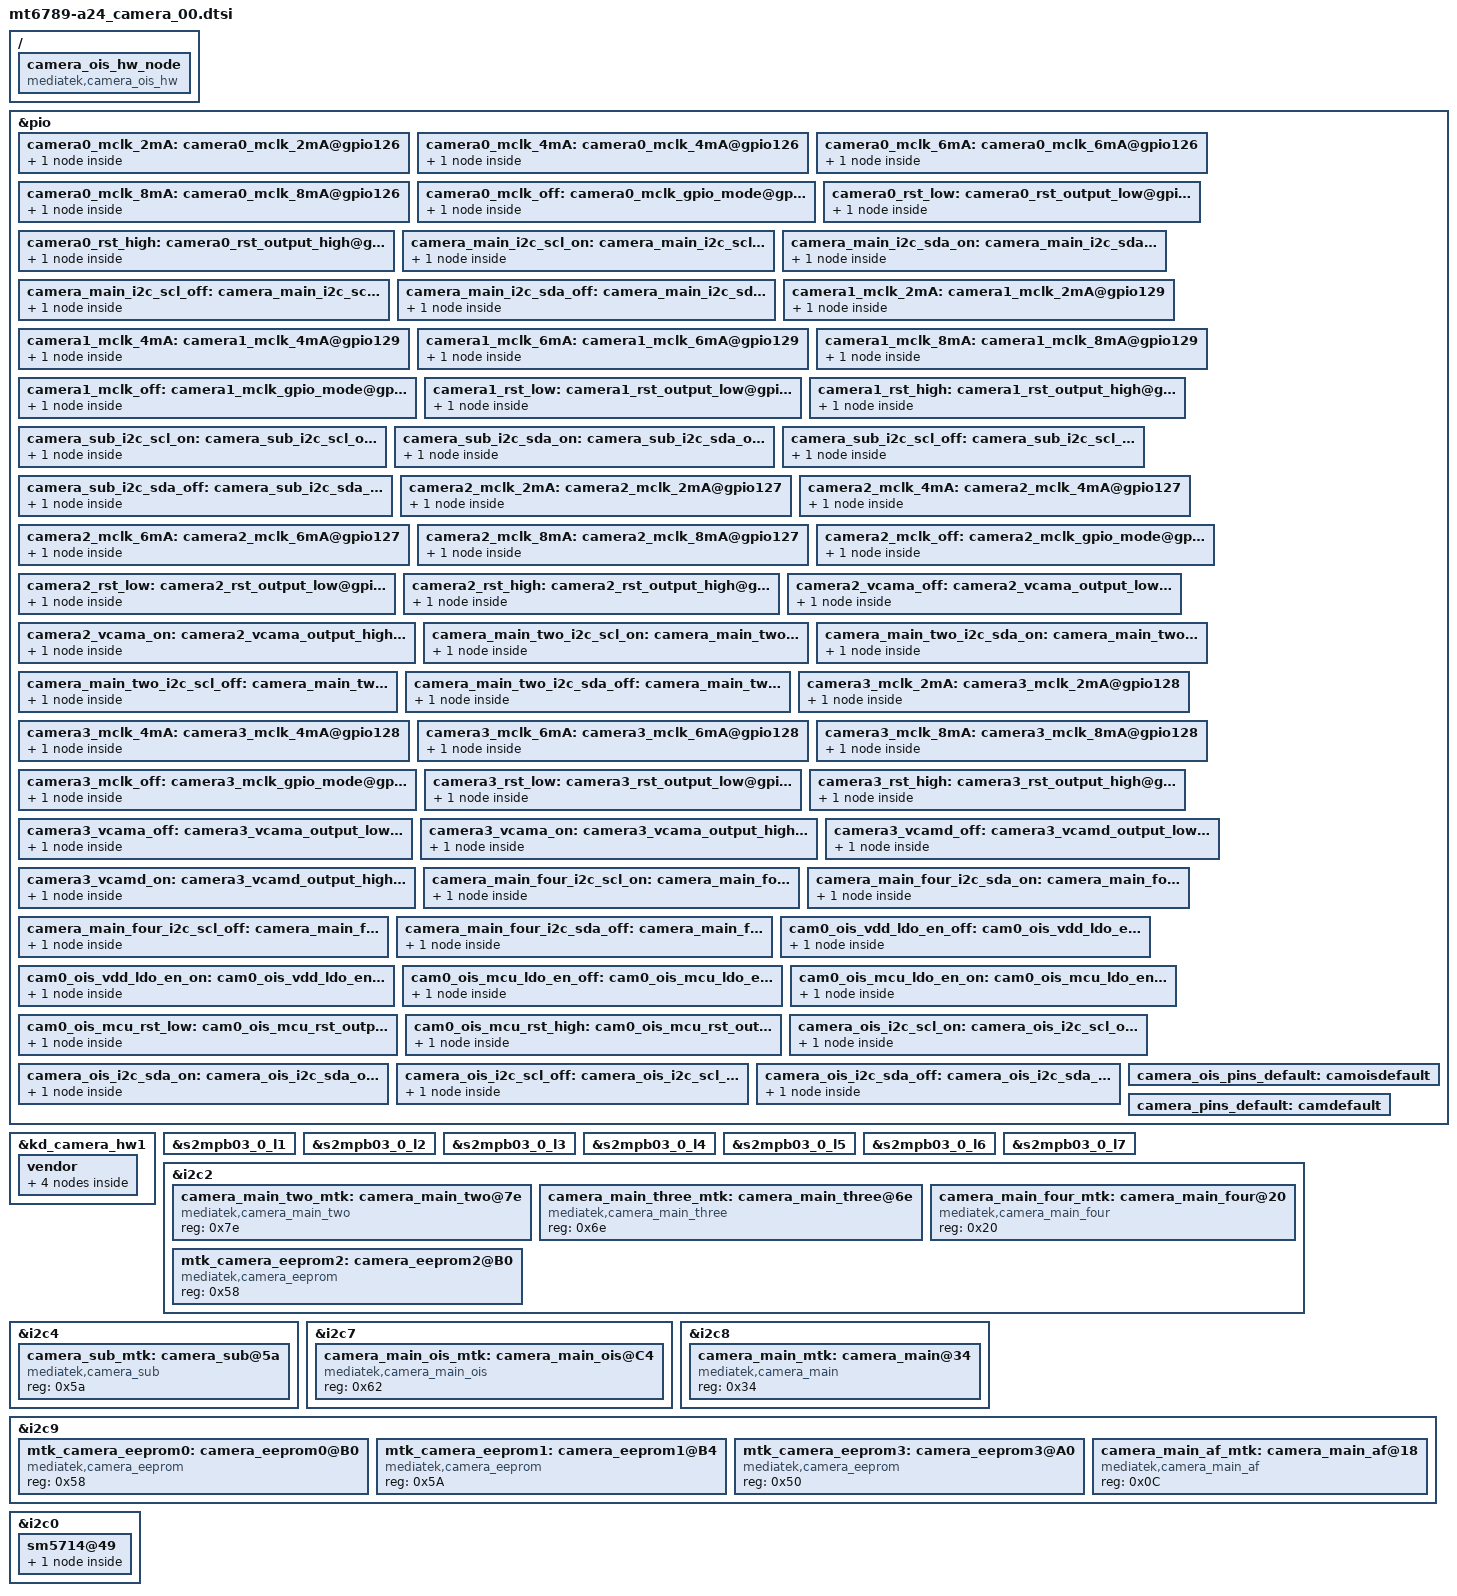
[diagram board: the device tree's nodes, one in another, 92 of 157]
/*
 * Copyright (c) 2021 MediaTek Inc.
 *
 * This program is free software; you can redistribute it and/or modify
 * it under the terms of the GNU General Public License version 2 as
 * published by the Free Software Foundation.
 *
 * This program is distributed in the hope that it will be useful,
 * but WITHOUT ANY WARRANTY; without even the implied warranty of
 * MERCHANTABILITY or FITNESS FOR A PARTICULAR PURPOSE.  See the
 * GNU General Public License for more details.
 */

/********  A24-LTE Board  ***********
 *    SW          :   HW   : Sensor
 * camera0(Wide)  : RCAM1  : S5KJN1
 * camera1(Front) : FCAM   : IMX258
 * camera2(UW)    : RCAM2  : GC5035
 * camera3(Macro) : RCAM3  : GC02M1
 ***********************************/

/* CAMERA GPIO standardization */
&pio {
	/****************  Camera0  ***************/
	// MCLK
	camera0_mclk_2mA: camera0_mclk_2mA@gpio126 {
		pins_cmd_dat {
			pinmux = <PINMUX_GPIO126__FUNC_CMMCLK0>;
			drive-strength = <0>;
		};
	};
	camera0_mclk_4mA: camera0_mclk_4mA@gpio126 {
		pins_cmd_dat {
			pinmux = <PINMUX_GPIO126__FUNC_CMMCLK0>;
			drive-strength = <1>;
		};
	};
	camera0_mclk_6mA: camera0_mclk_6mA@gpio126 {
		pins_cmd_dat {
			pinmux = <PINMUX_GPIO126__FUNC_CMMCLK0>;
			drive-strength = <2>;
		};
	};
	camera0_mclk_8mA: camera0_mclk_8mA@gpio126 {
		pins_cmd_dat {
			pinmux = <PINMUX_GPIO126__FUNC_CMMCLK0>;
			drive-strength = <3>;
		};
	};
	camera0_mclk_off: camera0_mclk_gpio_mode@gpio99 {
		pins_cmd_dat {
			pinmux = <PINMUX_GPIO126__FUNC_GPIO126>;
			drive-strength = <3>;
		};
	};

	// Reset
	camera0_rst_low: camera0_rst_output_low@gpio16 {
		pins_cmd_dat {
			pinmux = <PINMUX_GPIO16__FUNC_GPIO16>;
			output-low;
		};
	};
	camera0_rst_high: camera0_rst_output_high@gpio16 {
		pins_cmd_dat {
			pinmux = <PINMUX_GPIO16__FUNC_GPIO16>;
			output-high;
		};
	};

	// I2C
	camera_main_i2c_scl_on: camera_main_i2c_scl_on@gpio146 {
		pins_cmd_dat {
			pinmux = <PINMUX_GPIO146__FUNC_SCL8>;
			bias-disable;
		};
	};
	camera_main_i2c_sda_on: camera_main_i2c_sda_on@gpio147 {
		pins_cmd_dat {
			pinmux = <PINMUX_GPIO147__FUNC_SDA8>;
			bias-disable;
		};
	};
	camera_main_i2c_scl_off: camera_main_i2c_scl_off@gpio146 {
		pins_cmd_dat {
			pinmux = <PINMUX_GPIO146__FUNC_GPIO146>;
			bias-disable;
		};
	};
	camera_main_i2c_sda_off: camera_main_i2c_sda_off@gpio147 {
		pins_cmd_dat {
			pinmux = <PINMUX_GPIO147__FUNC_GPIO147>;
			bias-disable;
		};
	};

	/****************  Camera1  ***************/
	// MCLK
	camera1_mclk_2mA: camera1_mclk_2mA@gpio129 {
		pins_cmd_dat {
			pinmux = <PINMUX_GPIO129__FUNC_CMMCLK3>;
			drive-strength = <0>;
		};
	};
	camera1_mclk_4mA: camera1_mclk_4mA@gpio129 {
		pins_cmd_dat {
			pinmux = <PINMUX_GPIO129__FUNC_CMMCLK3>;
			drive-strength = <1>;
		};
	};
	camera1_mclk_6mA: camera1_mclk_6mA@gpio129 {
		pins_cmd_dat {
			pinmux = <PINMUX_GPIO129__FUNC_CMMCLK3>;
			drive-strength = <2>;
		};
	};
	camera1_mclk_8mA: camera1_mclk_8mA@gpio129 {
		pins_cmd_dat {
			pinmux = <PINMUX_GPIO129__FUNC_CMMCLK3>;
			drive-strength = <3>;
		};
	};
	camera1_mclk_off: camera1_mclk_gpio_mode@gpio129 {
		pins_cmd_dat {
			pinmux = <PINMUX_GPIO129__FUNC_GPIO129>;
			drive-strength = <1>;
		};
	};

	// Reset
	camera1_rst_low: camera1_rst_output_low@gpio15 {
		pins_cmd_dat {
			pinmux = <PINMUX_GPIO15__FUNC_GPIO15>;
			output-low;
		};
	};
	camera1_rst_high: camera1_rst_output_high@gpio15 {
		pins_cmd_dat {
			pinmux = <PINMUX_GPIO15__FUNC_GPIO15>;
			output-high;
		};
	};

	// I2C
	camera_sub_i2c_scl_on: camera_sub_i2c_scl_on@gpio138 {
		pins_cmd_dat {
			pinmux = <PINMUX_GPIO138__FUNC_SCL4>;
			bias-pull-up;
		};
	};
	camera_sub_i2c_sda_on: camera_sub_i2c_sda_on@gpio139 {
		pins_cmd_dat {
			pinmux = <PINMUX_GPIO139__FUNC_SDA4>;
			bias-pull-up;
		};
	};
	camera_sub_i2c_scl_off: camera_sub_i2c_scl_off@gpio138 {
		pins_cmd_dat {
			pinmux = <PINMUX_GPIO138__FUNC_GPIO138>;
			bias-pull-down;
		};
	};
	camera_sub_i2c_sda_off: camera_sub_i2c_sda_off@gpio139 {
		pins_cmd_dat {
			pinmux = <PINMUX_GPIO139__FUNC_GPIO139>;
			bias-pull-down;
		};
	};

	/****************  Camera2  ***************/
	// MCLK
	camera2_mclk_2mA: camera2_mclk_2mA@gpio127 {
		pins_cmd_dat {
			pinmux = <PINMUX_GPIO127__FUNC_CMMCLK1>;
			drive-strength = <0>;
		};
	};
	camera2_mclk_4mA: camera2_mclk_4mA@gpio127 {
		pins_cmd_dat {
			pinmux = <PINMUX_GPIO127__FUNC_CMMCLK1>;
			drive-strength = <1>;
		};
	};
	camera2_mclk_6mA: camera2_mclk_6mA@gpio127 {
		pins_cmd_dat {
			pinmux = <PINMUX_GPIO127__FUNC_CMMCLK1>;
			drive-strength = <2>;
		};
	};
	camera2_mclk_8mA: camera2_mclk_8mA@gpio127 {
		pins_cmd_dat {
			pinmux = <PINMUX_GPIO127__FUNC_CMMCLK1>;
			drive-strength = <3>;
		};
	};
	camera2_mclk_off: camera2_mclk_gpio_mode@gpio127 {
		pins_cmd_dat {
			pinmux = <PINMUX_GPIO127__FUNC_GPIO127>;
			drive-strength = <1>;
		};
	};

	// Reset
	camera2_rst_low: camera2_rst_output_low@gpio18 {
		pins_cmd_dat {
			pinmux = <PINMUX_GPIO18__FUNC_GPIO18>;
			output-low;
		};
	};
	camera2_rst_high: camera2_rst_output_high@gpio18 {
		pins_cmd_dat {
			pinmux = <PINMUX_GPIO18__FUNC_GPIO18>;
			output-high;
		};
	};

	// AVDD
	camera2_vcama_off: camera2_vcama_output_low@gpio34 {
		pins_cmd_dat {
			pinmux = <PINMUX_GPIO34__FUNC_GPIO34>;
			output-low;
		};
	};
	camera2_vcama_on: camera2_vcama_output_high@gpio34 {
		pins_cmd_dat {
			pinmux = <PINMUX_GPIO34__FUNC_GPIO34>;
			output-high;
		};
	};

	// I2C
	camera_main_two_i2c_scl_on: camera_main_two_i2c_scl_on@gpio134 {
		pins_cmd_dat {
			pinmux = <PINMUX_GPIO134__FUNC_SCL2>;
			bias-pull-up;
		};
	};
	camera_main_two_i2c_sda_on: camera_main_two_i2c_sda_on@gpio135 {
		pins_cmd_dat {
			pinmux = <PINMUX_GPIO135__FUNC_SDA2>;
			bias-pull-up;
		};
	};
	camera_main_two_i2c_scl_off: camera_main_two_i2c_scl_off@gpio134 {
		pins_cmd_dat {
			pinmux = <PINMUX_GPIO134__FUNC_GPIO134>;
			bias-pull-down;
		};
	};
	camera_main_two_i2c_sda_off: camera_main_two_i2c_sda_off@gpio135 {
		pins_cmd_dat {
			pinmux = <PINMUX_GPIO135__FUNC_GPIO135>;
			bias-pull-down;
		};
	};

	/****************  Camera3  ***************/
	// MCLK
	camera3_mclk_2mA: camera3_mclk_2mA@gpio128 {
		pins_cmd_dat {
			pinmux = <PINMUX_GPIO128__FUNC_CMMCLK2>;
			drive-strength = <0>;
		};
	};
	camera3_mclk_4mA: camera3_mclk_4mA@gpio128 {
		pins_cmd_dat {
			pinmux = <PINMUX_GPIO128__FUNC_CMMCLK2>;
			drive-strength = <1>;
		};
	};
	camera3_mclk_6mA: camera3_mclk_6mA@gpio128 {
		pins_cmd_dat {
			pinmux = <PINMUX_GPIO128__FUNC_CMMCLK2>;
			drive-strength = <2>;
		};
	};
	camera3_mclk_8mA: camera3_mclk_8mA@gpio128 {
		pins_cmd_dat {
			pinmux = <PINMUX_GPIO128__FUNC_CMMCLK2>;
			drive-strength = <3>;
		};
	};
	camera3_mclk_off: camera3_mclk_gpio_mode@gpio128 {
		pins_cmd_dat {
			pinmux = <PINMUX_GPIO128__FUNC_GPIO128>;
			drive-strength = <3>;
		};
	};

	// Reset
	camera3_rst_low: camera3_rst_output_low@gpio22 {
		pins_cmd_dat {
			pinmux = <PINMUX_GPIO22__FUNC_GPIO22>;
			output-low;
		};
	};
	camera3_rst_high: camera3_rst_output_high@gpio22 {
		pins_cmd_dat {
			pinmux = <PINMUX_GPIO22__FUNC_GPIO22>;
			output-high;
		};
	};

	// AVDD
	camera3_vcama_off: camera3_vcama_output_low@gpio98 {
		pins_cmd_dat {
			pinmux = <PINMUX_GPIO98__FUNC_GPIO98>;
			output-low;
		};
	};
	camera3_vcama_on: camera3_vcama_output_high@gpio98 {
		pins_cmd_dat {
			pinmux = <PINMUX_GPIO98__FUNC_GPIO98>;
			output-high;
		};
	};

	// DVDD
	camera3_vcamd_off: camera3_vcamd_output_low@gpio98 {
		pins_cmd_dat {
			pinmux = <PINMUX_GPIO98__FUNC_GPIO98>;
			output-low;
		};
	};
	camera3_vcamd_on: camera3_vcamd_output_high@gpio98 {
		pins_cmd_dat {
			pinmux = <PINMUX_GPIO98__FUNC_GPIO98>;
			output-high;
		};
	};

	// I2C
	camera_main_four_i2c_scl_on: camera_main_four_i2c_scl_on@gpio134 {
		pins_cmd_dat {
			pinmux = <PINMUX_GPIO134__FUNC_SCL2>;
			bias-pull-up;
		};
	};
	camera_main_four_i2c_sda_on: camera_main_four_i2c_sda_on@gpio135 {
		pins_cmd_dat {
			pinmux = <PINMUX_GPIO135__FUNC_SDA2>;
			bias-pull-up;
		};
	};
	camera_main_four_i2c_scl_off: camera_main_four_i2c_scl_off@gpio134 {
		pins_cmd_dat {
			pinmux = <PINMUX_GPIO134__FUNC_GPIO134>;
			bias-pull-down;
		};
	};
	camera_main_four_i2c_sda_off: camera_main_four_i2c_sda_off@gpio135 {
		pins_cmd_dat {
			pinmux = <PINMUX_GPIO135__FUNC_GPIO135>;
			bias-pull-down;
		};
	};

	/****************  Camera OIS  ***************/
	// OIS_VDD_LDO_EN
	cam0_ois_vdd_ldo_en_off: cam0_ois_vdd_ldo_en_output_low@gpio107 {
		pins_cmd_dat {
			pinmux = <PINMUX_GPIO107__FUNC_GPIO107>;
			output-low;
		};
	};
	cam0_ois_vdd_ldo_en_on: cam0_ois_vdd_ldo_en_output_high@gpio107 {
		pins_cmd_dat {
			pinmux = <PINMUX_GPIO107__FUNC_GPIO107>;
			output-high;
		};
	};

	// OIS_MCU_LDO_EN
	cam0_ois_mcu_ldo_en_off: cam0_ois_mcu_ldo_en_output_low@gpio97 {
		pins_cmd_dat {
			pinmux = <PINMUX_GPIO97__FUNC_GPIO97>;
			output-low;
		};
	};
	cam0_ois_mcu_ldo_en_on: cam0_ois_mcu_ldo_en_output_high@gpio97 {
		pins_cmd_dat {
			pinmux = <PINMUX_GPIO97__FUNC_GPIO97>;
			output-high;
		};
	};

	// OIS_MCU_RST
	cam0_ois_mcu_rst_low: cam0_ois_mcu_rst_output_low@gpio96 {
		pins_cmd_dat {
			pinmux = <PINMUX_GPIO96__FUNC_GPIO96>;
			output-low;
		};
	};
	cam0_ois_mcu_rst_high: cam0_ois_mcu_rst_output_high@gpio96 {
		pins_cmd_dat {
			pinmux = <PINMUX_GPIO96__FUNC_GPIO96>;
			output-high;
		};
	};

	// OIS I2C
	camera_ois_i2c_scl_on: camera_ois_i2c_scl_on@gpio144 {
		pins_cmd_dat {
			pinmux = <PINMUX_GPIO144__FUNC_SCL7>;
			bias-pull-up;
		};
	};
	camera_ois_i2c_sda_on: camera_ois_i2c_sda_on@gpio145 {
		pins_cmd_dat {
			pinmux = <PINMUX_GPIO145__FUNC_SDA7>;
			bias-pull-up;
		};
	};
	camera_ois_i2c_scl_off: camera_ois_i2c_scl_off@gpio144 {
		pins_cmd_dat {
			pinmux = <PINMUX_GPIO144__FUNC_GPIO144>;
			bias-pull-down;
		};
	};
	camera_ois_i2c_sda_off: camera_ois_i2c_sda_off@gpio145 {
		pins_cmd_dat {
			pinmux = <PINMUX_GPIO145__FUNC_GPIO145>;
			bias-pull-down;
		};
	};

	camera_ois_pins_default: camoisdefault {
	};

/****************  default  ***************/
	camera_pins_default: camdefault {
	};
};

&kd_camera_hw1 {
	pinctrl-names = "default",
			"cam0_mclk_off",
			"cam0_mclk_2mA", "cam0_mclk_4mA",
			"cam0_mclk_6mA", "cam0_mclk_8mA",
			"cam0_rst0", "cam0_rst1",

			"cam1_mclk_off",
			"cam1_mclk_2mA", "cam1_mclk_4mA",
			"cam1_mclk_6mA", "cam1_mclk_8mA",
			"cam1_rst0", "cam1_rst1",

			"cam2_mclk_off",
			"cam2_mclk_2mA", "cam2_mclk_4mA",
			"cam2_mclk_6mA", "cam2_mclk_8mA",
			"cam2_rst0", "cam2_rst1",
			"cam2_vcama_off", "cam2_vcama_on",

			"cam3_mclk_off",
			"cam3_mclk_2mA", "cam3_mclk_4mA",
			"cam3_mclk_6mA", "cam3_mclk_8mA",
			"cam3_rst0", "cam3_rst1",
			"cam3_vcama_off", "cam3_vcama_on",
			"cam3_vcamd_off", "cam3_vcamd_on";

	pinctrl-0 = <&camera_pins_default>;

	pinctrl-1 = <&camera0_mclk_off>;
	pinctrl-2 = <&camera0_mclk_2mA>;
	pinctrl-3 = <&camera0_mclk_4mA>;
	pinctrl-4 = <&camera0_mclk_6mA>;
	pinctrl-5 = <&camera0_mclk_8mA>;
	pinctrl-6 = <&camera0_rst_low>;
	pinctrl-7 = <&camera0_rst_high>;

	pinctrl-8 = <&camera1_mclk_off>;
	pinctrl-9 = <&camera1_mclk_2mA>;
	pinctrl-10 = <&camera1_mclk_4mA>;
	pinctrl-11 = <&camera1_mclk_6mA>;
	pinctrl-12 = <&camera1_mclk_8mA>;
	pinctrl-13 = <&camera1_rst_low>;
	pinctrl-14 = <&camera1_rst_high>;

	pinctrl-15 = <&camera2_mclk_off>;
	pinctrl-16 = <&camera2_mclk_2mA>;
	pinctrl-17 = <&camera2_mclk_4mA>;
	pinctrl-18 = <&camera2_mclk_6mA>;
	pinctrl-19 = <&camera2_mclk_8mA>;
	pinctrl-20 = <&camera2_rst_low>;
	pinctrl-21 = <&camera2_rst_high>;
	pinctrl-22 = <&camera2_vcama_off>;
	pinctrl-23 = <&camera2_vcama_on>;

	pinctrl-24 = <&camera3_mclk_off>;
	pinctrl-25 = <&camera3_mclk_2mA>;
	pinctrl-26 = <&camera3_mclk_4mA>;
	pinctrl-27 = <&camera3_mclk_6mA>;
	pinctrl-28 = <&camera3_mclk_8mA>;
	pinctrl-29 = <&camera3_rst_low>;
	pinctrl-30 = <&camera3_rst_high>;
	pinctrl-31 = <&camera3_vcama_off>;
	pinctrl-32 = <&camera3_vcama_on>;
	pinctrl-33 = <&camera3_vcamd_off>;
	pinctrl-34 = <&camera3_vcamd_on>;

	/********* Regulator setting **************/
	// Camera0
	cam0_vcama-supply = <&s2mpb03_0_l5>;
	cam0_vcamd-supply = <&s2mpb03_0_l1>;
	cam0_vcamio-supply = <&s2mpb03_0_l3>;
	cam0_vcamaf-supply = <&s2mpb03_0_l7>;

	// Camera1
	cam1_vcama-supply = <&s2mpb03_0_l6>;
	cam1_vcamd-supply = <&s2mpb03_0_l2>;
	cam1_vcamio-supply = <&s2mpb03_0_l3>;

	// Camera2
	cam2_vcamd-supply = <&s2mpb03_0_l4>;
	cam2_vcamio-supply = <&s2mpb03_0_l3>;

	// Camera3
	cam3_vcamio-supply = <&s2mpb03_0_l3>;

	status = "okay";
	vendor {
		rear_sensor_id = <120>;     /* SENSOR_NAME_S5KJN1*/
		front_sensor_id = <121>;    /* SENSOR_NAME_IMX258 */
		rear2_sensor_id = <210>;    /* SENSOR_NAME_GC5035 */
		rear3_sensor_id = <211>;    /* SENSOR_NAME_GC02M1 */

		use_dualcam_set_cal;
		use_module_check;
		//skip_cal_loading;
		//check_final_cam_module;
		max_supported_camera = <2>; // 4
		supported_cameraId = <0 1>; // 0 1 50 54
		/* REAR, FRONT, DUAL_REAR_PORTRAIT_WIDE(Bokeh), REAR_2, REAR_3(Macro) */

		max_camera_num = <4>;
		camera_info0 {             /* 0 : rear -  S5KJN1 */
			isp = <0>;             /* 0 : INT , 1 : EXT , 2 : SOC */
			cal_memory = <2>;      /* 0 : N , 1 : FROM , 2 : EEPROM , 3 : OTP  */
			read_version = <0>;    /* 0 : SYSFS , 1 : CAMON */
			core_voltage = <0>;    /* 0 : N , 1 : Y  */
			upgrade = <0>;         /* 0 : N , 1 : SYSFS , 2 : CAMON */
			companion = <0>;       /* 0 : N , 1 : Y  */
			ois = <1>;             /* 0 : N , 1 : Y  */
			valid = <1>;           /* 0 : INVALID, 1 : VALID */
			dual_open = <0>;       /* 0 : SINGLE_OPEN , 1 : DUAL_OPEN */
			position = <0>;        /* 0 : Rear, 1:Front, 2:Rear2, 3:Front2, 4:Rear3, 6:Rear4 */
			//includes_sub = <4>;    /* include this for common eeprom. <_position_> - position of the sub camera */
			afcal_type=<20>;       /* output format - 1: Near, Middle..., Far , 20: Near, Far, Middle... */
			use_adaptive_mipi=<1>;  /* 0 : N, 1 : Y */
		};
		camera_info1 {             /* 1 : front1 - S5K4HAYXF */
			isp = <0>;             /* 0 : INT , 1 : EXT , 2 : SOC */
			cal_memory = <3>;      /* 0 : N , 1 : FROM , 2 : EEPROM , 3 : OTP  */
			read_version = <0>;    /* 0 : SYSFS , 1 : CAMON */
			core_voltage = <0>;    /* 0 : N , 1 : Y  */
			upgrade = <0>;         /* 0 : N , 1 : SYSFS , 2 : CAMON */
			companion = <0>;       /* 0 : N , 1 : Y  */
			ois = <0>;             /* 0 : N , 1 : Y  */
			valid = <1>;           /* 0 : INVALID, 1 : VALID */
			dual_open = <0>;       /* 0 : SINGLE_OPEN , 1 : DUAL_OPEN */
			position = <1>;        /* 0 : Rear, 1:Front, 2:Rear2, 3:Front2, 4:Rear3, 6:Rear4 */
			use_adaptive_mipi=<0>;  /* 0 : N, 1 : Y */
		};
		camera_info2 {             /* 2 : rear2 - GC5035 */
			isp = <0>;             /* 0 : INT , 1 : EXT , 2 : SOC */
			cal_memory = <3>;      /* 0 : N , 1 : FROM , 2 : EEPROM , 3 : OTP  */
			read_version = <0>;    /* 0 : SYSFS , 1 : CAMON */
			core_voltage = <0>;    /* 0 : N , 1 : Y  */
			upgrade = <0>;         /* 0 : N , 1 : SYSFS , 2 : CAMON */
			companion = <0>;       /* 0 : N , 1 : Y  */
			ois = <0>;             /* 0 : N , 1 : Y  */
			valid = <1>;           /* 0 : INVALID, 1 : VALID */
			dual_open = <0>;       /* 0 : SINGLE_OPEN , 1 : DUAL_OPEN */
			position = <2>;        /* 0 : Rear, 1:Front, 2:Rear2, 3:Front2, 4:Rear3, 6:Rear4 */
			use_adaptive_mipi=<0>;  /* 0 : N, 1 : Y */
		};
		camera_info3{             /* 3 : rear3 - GC02M1 */
			isp = <0>;             /* 0 : INT , 1 : EXT , 2 : SOC */
			cal_memory = <2>;      /* 0 : N , 1 : FROM , 2 : EEPROM , 3 : OTP  */
			read_version = <0>;    /* 0 : SYSFS , 1 : CAMON */
			core_voltage = <0>;    /* 0 : N , 1 : Y  */
			upgrade = <0>;         /* 0 : N , 1 : SYSFS , 2 : CAMON */
			companion = <0>;       /* 0 : N , 1 : Y  */
			ois = <0>;             /* 0 : N , 1 : Y  */
			valid = <1>;           /* 0 : INVALID, 1 : VALID */
			dual_open = <0>;       /* 0 : SINGLE_OPEN , 1 : DUAL_OPEN */
			position = <4>;        /* 0 : Rear, 1:Front, 2:Rear2, 3:Front2, 4:Rear3, 6:Rear4 */
			use_adaptive_mipi=<0>;  /* 0 : N, 1 : Y */
		};
	};
};
/* CAMERA GPIO end */

/* CAMERA AF */
//&camera_af_hw_node {
//	vcamaf-supply = <&s2mpb03_0_l7>;
//	status = "okay";
//};
/* CAMERA AF end */

/* CAMERA OIS */
/ {
	fragment@cam_ois_drv {
		target-path = "/";
		__overlay__ {

			camera_ois_hw_node: camera_ois_hw_node {
				compatible = "mediatek,camera_ois_hw";
				pinctrl-names = "default",
						"cam0_ois_mcu_rst_0", "cam0_ois_mcu_rst_1",
						"cam0_ois_mcu_ldo_off", "cam0_ois_mcu_ldo_on",
						"cam0_ois_vdd_ldo_off", "cam0_ois_vdd_ldo_on";

				pinctrl-0 = <&camera_ois_pins_default>;
				pinctrl-1 = <&cam0_ois_mcu_rst_low>;
				pinctrl-2 = <&cam0_ois_mcu_rst_high>;
				pinctrl-3 = <&cam0_ois_mcu_ldo_en_off>;
				pinctrl-4 = <&cam0_ois_mcu_ldo_en_on>;
				pinctrl-5 = <&cam0_ois_vdd_ldo_en_off>;
				pinctrl-6 = <&cam0_ois_vdd_ldo_en_on>;

				cam0_vcamaf-supply = <&s2mpb03_0_l7>;

				status = "okay";
			};
		};
	};
};
/* CAMERA OIS end */

/* CAM PMIC */
&s2mpb03_0_l1 {
	regulator-min-microvolt = <1050000>;
	regulator-max-microvolt = <1100000>;
};
&s2mpb03_0_l2 {
	regulator-min-microvolt = <1200000>;
	regulator-max-microvolt = <1200000>;
};
&s2mpb03_0_l3 {
	regulator-min-microvolt = <1800000>;
	regulator-max-microvolt = <1800000>;
};
&s2mpb03_0_l4 {
	regulator-min-microvolt = <1100000>;
	regulator-max-microvolt = <1200000>;
};
&s2mpb03_0_l5 {
	regulator-min-microvolt = <2800000>;
	regulator-max-microvolt = <2900000>;
};
&s2mpb03_0_l6 {
	regulator-min-microvolt = <2800000>;
	regulator-max-microvolt = <2900000>;
};
&s2mpb03_0_l7 {
	regulator-min-microvolt = <2800000>;
	regulator-max-microvolt = <2900000>;
};

/*************************
 *     Cmaera I2C
 *************************/
&i2c2 {
	#address-cells = <1>;
	#size-cells = <0>;
	clock-frequency = <400000>;
	mediatek,use-open-drain;
	camera_main_two_mtk:camera_main_two@7e{
		compatible = "mediatek,camera_main_two";
		reg = <0x7e>;
		status = "okay";
	};

	camera_main_three_mtk:camera_main_three@6e {
		compatible = "mediatek,camera_main_three";
		reg = <0x6e>;
		status = "okay";
	};

	camera_main_four_mtk:camera_main_four@20 {
		compatible = "mediatek,camera_main_four";
		reg = <0x20>;
		status = "okay";
	};

	mtk_camera_eeprom2:camera_eeprom2@B0 {
		compatible = "mediatek,camera_eeprom";
		reg = <0x58>;
		status = "okay";
	};
};

&i2c4 {
	#address-cells = <1>;
	#size-cells = <0>;
	clock-frequency = <400000>;
	mediatek,use-open-drain;
	camera_sub_mtk:camera_sub@5a {
		compatible = "mediatek,camera_sub";
		reg = <0x5a>;
		status = "okay";
	};
};

&i2c7 {
	#address-cells = <1>;
	#size-cells = <0>;
	clock-frequency = <1000000>;
	mediatek,use-open-drain;
	camera_main_ois_mtk:camera_main_ois@C4 {
		compatible = "mediatek,camera_main_ois";
		reg = <0x62>;
		status = "okay";
	};
};

&i2c8 {
	#address-cells = <1>;
	#size-cells = <0>;
	clock-frequency = <1000000>;
	mediatek,use-open-drain;
	camera_main_mtk:camera_main@34{
		compatible = "mediatek,camera_main";
		reg = <0x34>;
		status = "okay";
	};
};

&i2c9 {
	#address-cells = <1>;
	#size-cells = <0>;
	clock-frequency = <400000>;
	mediatek,use-open-drain;

	/* Rear camera */
	mtk_camera_eeprom0:camera_eeprom0@B0 {
		compatible = "mediatek,camera_eeprom";
		reg = <0x58>;
		status = "okay";
	};

	mtk_camera_eeprom1:camera_eeprom1@B4 {
		compatible = "mediatek,camera_eeprom";
		reg = <0x5A>;
		status = "okay";
	};

	mtk_camera_eeprom3:camera_eeprom3@A0 {
		compatible = "mediatek,camera_eeprom";
		reg = <0x50>;
		status = "okay";
	};

	camera_main_af_mtk:camera_main_af@18 {
		compatible = "mediatek,camera_main_af";
		reg = <0x0C>;
		status = "okay";
	};
};

/*************************
 *     Flash LED
 *************************/
&i2c0 {
	sm5714@49 {
		sm5714-fled {
			status = "okay";
			compatible = "siliconmitus,sm5714-fled";
			flash-en-gpio = <&pio 150 0>;
			torch-en-gpio = <&pio 151 0>;

			flash-brightness = <0xA>; //0x0(300mA) ~ 0xF(1500mA) : 50mA Step
			preflash-brightness = <0x4>;
			torch-brightness = <0x4>; //0x0(50mA) ~ 0x7(225mA) : 25mA Step
			factory_current = <0x6>; //0x0(300mA)
			flashlight_current = <0 1 2 5 7>;
			timeout = <0xff>;
		};
	};
};
